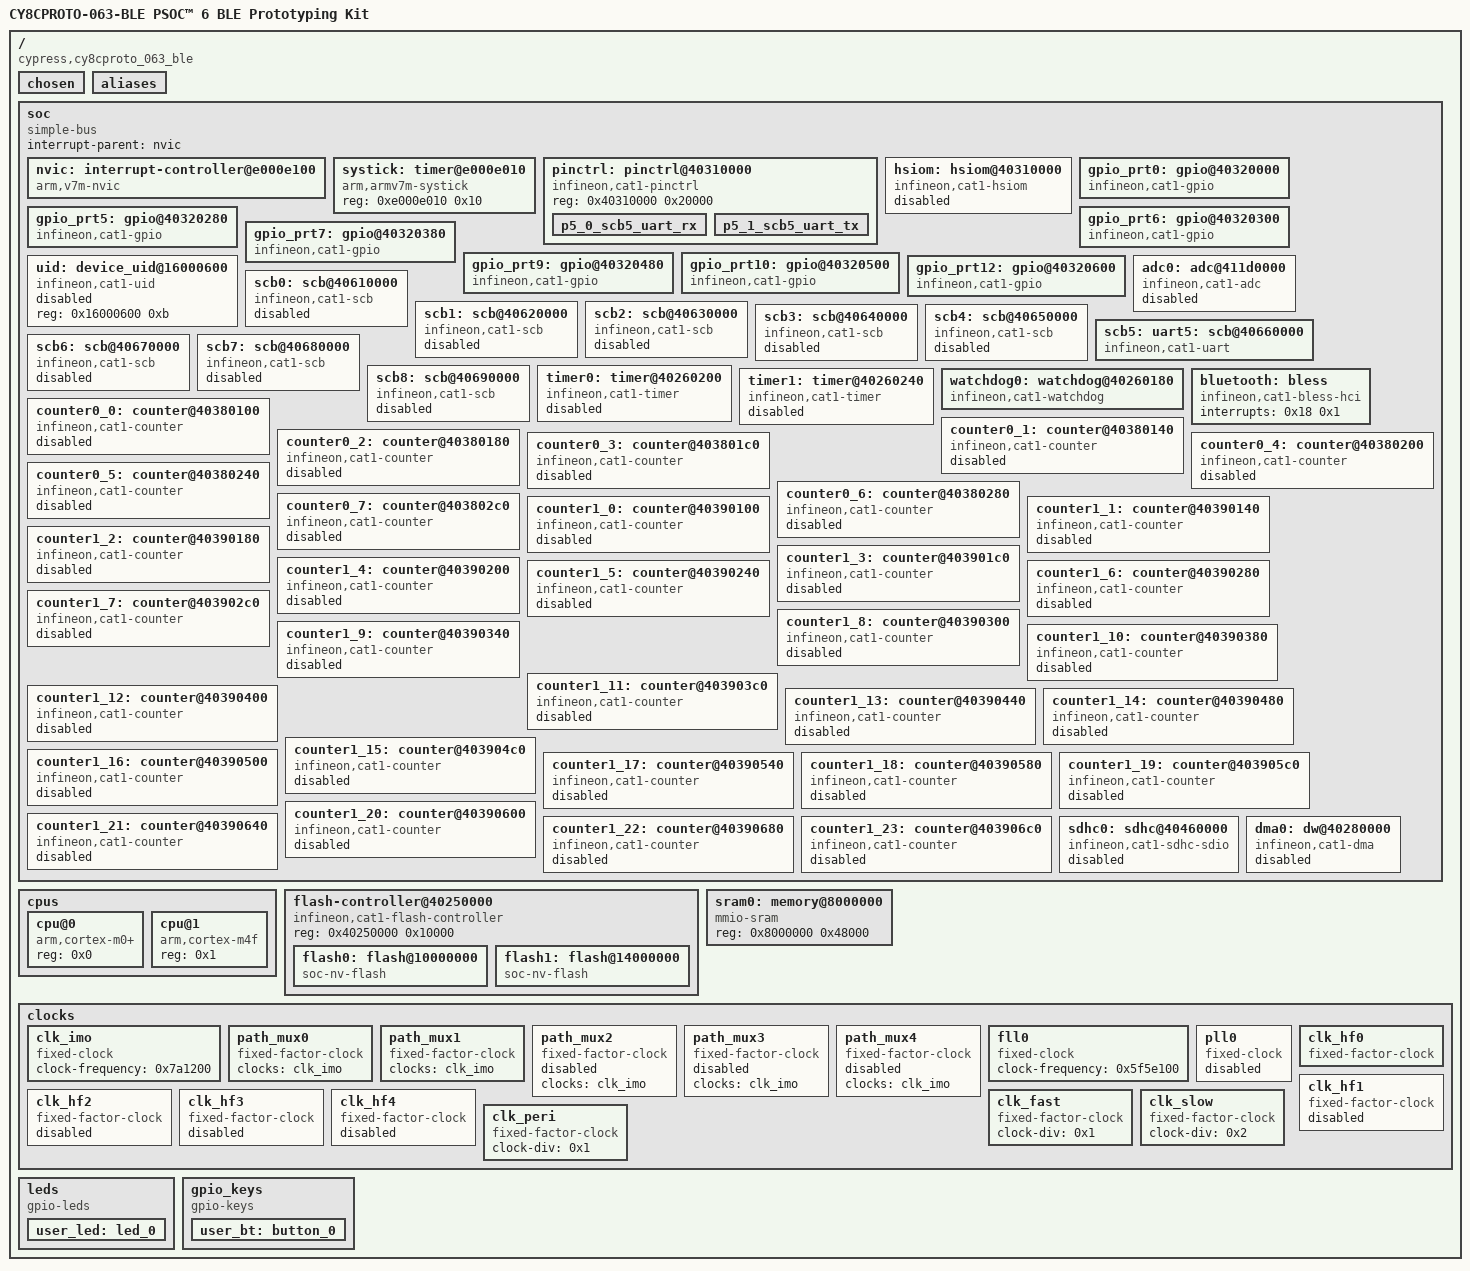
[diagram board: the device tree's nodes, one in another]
/dts-v1/;

/* node '/' defined in zephyr/dts/common/skeleton.dtsi:9 */
/ {
	#address-cells = < 0x1 >;                                /* in zephyr/dts/common/skeleton.dtsi:10 */
	#size-cells = < 0x1 >;                                   /* in zephyr/dts/common/skeleton.dtsi:11 */
	model = "CY8CPROTO-063-BLE PSOC™ 6 BLE Prototyping Kit"; /* in zephyr/boards/infineon/cy8cproto_063_ble/cy8cproto_063_ble.dts:15 */
	compatible = "cypress,cy8cproto_063_ble",
	             "cypress,PSOC6";                            /* in zephyr/boards/infineon/cy8cproto_063_ble/cy8cproto_063_ble.dts:16 */

	/* node '/chosen' defined in zephyr/dts/common/skeleton.dtsi:13 */
	chosen {
		zephyr,sram = &sram0;       /* in zephyr/boards/infineon/cy8cproto_063_ble/cy8cproto_063_ble.dts:26 */
		zephyr,flash = &flash0;     /* in zephyr/boards/infineon/cy8cproto_063_ble/cy8cproto_063_ble.dts:27 */
		zephyr,console = &uart5;    /* in zephyr/boards/infineon/cy8cproto_063_ble/cy8cproto_063_ble.dts:28 */
		zephyr,shell-uart = &uart5; /* in zephyr/boards/infineon/cy8cproto_063_ble/cy8cproto_063_ble.dts:29 */
		zephyr,bt-hci = &bluetooth; /* in zephyr/boards/infineon/cy8cproto_063_ble/cy8cproto_063_ble.dts:30 */
	};

	/* node '/aliases' defined in zephyr/dts/common/skeleton.dtsi:15 */
	aliases {
		uart-5 = &uart5;        /* in zephyr/boards/infineon/cy8cproto_063_ble/cy8cproto_063_ble.dts:19 */
		led0 = &user_led;       /* in zephyr/boards/infineon/cy8cproto_063_ble/cy8cproto_063_ble.dts:20 */
		sw0 = &user_bt;         /* in zephyr/boards/infineon/cy8cproto_063_ble/cy8cproto_063_ble.dts:21 */
		watchdog0 = &watchdog0; /* in zephyr/boards/infineon/cy8cproto_063_ble/cy8cproto_063_ble.dts:22 */
	};

	/* node '/soc' defined in zephyr/dts/arm/armv7-m.dtsi:6 */
	soc {
		#address-cells = < 0x1 >;     /* in zephyr/dts/arm/armv7-m.dtsi:7 */
		#size-cells = < 0x1 >;        /* in zephyr/dts/arm/armv7-m.dtsi:8 */
		compatible = "simple-bus";    /* in zephyr/dts/arm/armv7-m.dtsi:9 */
		interrupt-parent = < &nvic >; /* in zephyr/dts/arm/armv7-m.dtsi:10 */
		ranges;                       /* in zephyr/dts/arm/armv7-m.dtsi:11 */

		/* node '/soc/interrupt-controller@e000e100' defined in zephyr/dts/arm/armv7-m.dtsi:13 */
		nvic: interrupt-controller@e000e100 {
			#address-cells = < 0x1 >;            /* in zephyr/dts/arm/armv7-m.dtsi:14 */
			compatible = "arm,v7m-nvic";         /* in zephyr/dts/arm/armv7-m.dtsi:15 */
			reg = < 0xe000e100 0xc00 >;          /* in zephyr/dts/arm/armv7-m.dtsi:16 */
			interrupt-controller;                /* in zephyr/dts/arm/armv7-m.dtsi:17 */
			#interrupt-cells = < 0x2 >;          /* in zephyr/dts/arm/armv7-m.dtsi:18 */
			arm,num-irq-priority-bits = < 0x3 >; /* in zephyr/dts/arm/infineon/cat1a/mpns/CYBLE_416045_02.dtsi:12 */
			phandle = < 0x1 >;                   /* in zephyr/dts/arm/armv7-m.dtsi:10 */
		};

		/* node '/soc/timer@e000e010' defined in zephyr/dts/arm/armv7-m.dtsi:21 */
		systick: timer@e000e010 {
			compatible = "arm,armv7m-systick"; /* in zephyr/dts/arm/armv7-m.dtsi:22 */
			reg = < 0xe000e010 0x10 >;         /* in zephyr/dts/arm/armv7-m.dtsi:23 */
		};

		/* node '/soc/pinctrl@40310000' defined in zephyr/dts/arm/infineon/cat1a/psoc6_01/psoc6_01.dtsi:55 */
		pinctrl: pinctrl@40310000 {
			compatible = "infineon,cat1-pinctrl"; /* in zephyr/dts/arm/infineon/cat1a/psoc6_01/psoc6_01.dtsi:56 */
			reg = < 0x40310000 0x20000 >;         /* in zephyr/dts/arm/infineon/cat1a/psoc6_01/psoc6_01.dtsi:57 */
			#address-cells = < 0x1 >;             /* in zephyr/dts/arm/infineon/cat1a/psoc6_01/psoc6_01.dtsi:58 */
			#size-cells = < 0x0 >;                /* in zephyr/dts/arm/infineon/cat1a/psoc6_01/psoc6_01.dtsi:59 */

			/* node '/soc/pinctrl@40310000/p5_0_scb5_uart_rx' defined in zephyr/dts/arm/infineon/cat1a/psoc6_01/psoc6_01.43-smt.dtsi:125 */
			p5_0_scb5_uart_rx: p5_0_scb5_uart_rx {
				pinmux = < 0x120005 >; /* in zephyr/dts/arm/infineon/cat1a/psoc6_01/psoc6_01.43-smt.dtsi:126 */
				input-enable;          /* in zephyr/boards/infineon/cy8cproto_063_ble/cy8cproto_063_ble-pinctrl.dtsi:13 */
				phandle = < 0x3 >;     /* in zephyr/boards/infineon/cy8cproto_063_ble/cy8cproto_063_ble.dts:89 */
			};

			/* node '/soc/pinctrl@40310000/p5_1_scb5_uart_tx' defined in zephyr/dts/arm/infineon/cat1a/psoc6_01/psoc6_01.43-smt.dtsi:142 */
			p5_1_scb5_uart_tx: p5_1_scb5_uart_tx {
				pinmux = < 0x120105 >; /* in zephyr/dts/arm/infineon/cat1a/psoc6_01/psoc6_01.43-smt.dtsi:143 */
				drive-push-pull;       /* in zephyr/boards/infineon/cy8cproto_063_ble/cy8cproto_063_ble-pinctrl.dtsi:9 */
				phandle = < 0x2 >;     /* in zephyr/boards/infineon/cy8cproto_063_ble/cy8cproto_063_ble.dts:89 */
			};
		};

		/* node '/soc/hsiom@40310000' defined in zephyr/dts/arm/infineon/cat1a/psoc6_01/psoc6_01.dtsi:62 */
		hsiom: hsiom@40310000 {
			compatible = "infineon,cat1-hsiom"; /* in zephyr/dts/arm/infineon/cat1a/psoc6_01/psoc6_01.dtsi:63 */
			reg = < 0x40310000 0x4000 >;        /* in zephyr/dts/arm/infineon/cat1a/psoc6_01/psoc6_01.dtsi:64 */
			interrupts = < 0xf 0x6 >,
			             < 0x10 0x6 >;          /* in zephyr/dts/arm/infineon/cat1a/psoc6_01/psoc6_01.dtsi:65 */
			status = "disabled";                /* in zephyr/dts/arm/infineon/cat1a/psoc6_01/psoc6_01.dtsi:66 */
		};

		/* node '/soc/gpio@40320000' defined in zephyr/dts/arm/infineon/cat1a/psoc6_01/psoc6_01.dtsi:69 */
		gpio_prt0: gpio@40320000 {
			compatible = "infineon,cat1-gpio"; /* in zephyr/dts/arm/infineon/cat1a/psoc6_01/psoc6_01.dtsi:70 */
			reg = < 0x40320000 0x80 >;         /* in zephyr/dts/arm/infineon/cat1a/psoc6_01/psoc6_01.dtsi:71 */
			interrupts = < 0x0 0x6 >;          /* in zephyr/dts/arm/infineon/cat1a/psoc6_01/psoc6_01.dtsi:72 */
			gpio-controller;                   /* in zephyr/dts/arm/infineon/cat1a/psoc6_01/psoc6_01.dtsi:73 */
			ngpios = < 0x6 >;                  /* in zephyr/dts/arm/infineon/cat1a/psoc6_01/psoc6_01.dtsi:74 */
			#gpio-cells = < 0x2 >;             /* in zephyr/dts/arm/infineon/cat1a/psoc6_01/psoc6_01.dtsi:76 */
			status = "okay";                   /* in zephyr/boards/infineon/cy8cproto_063_ble/cy8cproto_063_ble.dts:56 */
			phandle = < 0xb >;                 /* in zephyr/boards/infineon/cy8cproto_063_ble/cy8cproto_063_ble.dts:49 */
		};

		/* node '/soc/gpio@40320280' defined in zephyr/dts/arm/infineon/cat1a/psoc6_01/psoc6_01.dtsi:119 */
		gpio_prt5: gpio@40320280 {
			compatible = "infineon,cat1-gpio"; /* in zephyr/dts/arm/infineon/cat1a/psoc6_01/psoc6_01.dtsi:120 */
			reg = < 0x40320280 0x80 >;         /* in zephyr/dts/arm/infineon/cat1a/psoc6_01/psoc6_01.dtsi:121 */
			interrupts = < 0x5 0x6 >;          /* in zephyr/dts/arm/infineon/cat1a/psoc6_01/psoc6_01.dtsi:122 */
			gpio-controller;                   /* in zephyr/dts/arm/infineon/cat1a/psoc6_01/psoc6_01.dtsi:123 */
			ngpios = < 0x8 >;                  /* in zephyr/dts/arm/infineon/cat1a/psoc6_01/psoc6_01.dtsi:124 */
			#gpio-cells = < 0x2 >;             /* in zephyr/dts/arm/infineon/cat1a/psoc6_01/psoc6_01.dtsi:126 */
			status = "okay";                   /* in zephyr/boards/infineon/cy8cproto_063_ble/cy8cproto_063_ble.dts:60 */
		};

		/* node '/soc/gpio@40320300' defined in zephyr/dts/arm/infineon/cat1a/psoc6_01/psoc6_01.dtsi:129 */
		gpio_prt6: gpio@40320300 {
			compatible = "infineon,cat1-gpio"; /* in zephyr/dts/arm/infineon/cat1a/psoc6_01/psoc6_01.dtsi:130 */
			reg = < 0x40320300 0x80 >;         /* in zephyr/dts/arm/infineon/cat1a/psoc6_01/psoc6_01.dtsi:131 */
			interrupts = < 0x6 0x6 >;          /* in zephyr/dts/arm/infineon/cat1a/psoc6_01/psoc6_01.dtsi:132 */
			gpio-controller;                   /* in zephyr/dts/arm/infineon/cat1a/psoc6_01/psoc6_01.dtsi:133 */
			ngpios = < 0x8 >;                  /* in zephyr/dts/arm/infineon/cat1a/psoc6_01/psoc6_01.dtsi:134 */
			#gpio-cells = < 0x2 >;             /* in zephyr/dts/arm/infineon/cat1a/psoc6_01/psoc6_01.dtsi:136 */
			status = "okay";                   /* in zephyr/boards/infineon/cy8cproto_063_ble/cy8cproto_063_ble.dts:64 */
			phandle = < 0xa >;                 /* in zephyr/boards/infineon/cy8cproto_063_ble/cy8cproto_063_ble.dts:40 */
		};

		/* node '/soc/gpio@40320380' defined in zephyr/dts/arm/infineon/cat1a/psoc6_01/psoc6_01.dtsi:139 */
		gpio_prt7: gpio@40320380 {
			compatible = "infineon,cat1-gpio"; /* in zephyr/dts/arm/infineon/cat1a/psoc6_01/psoc6_01.dtsi:140 */
			reg = < 0x40320380 0x80 >;         /* in zephyr/dts/arm/infineon/cat1a/psoc6_01/psoc6_01.dtsi:141 */
			interrupts = < 0x7 0x6 >;          /* in zephyr/dts/arm/infineon/cat1a/psoc6_01/psoc6_01.dtsi:142 */
			gpio-controller;                   /* in zephyr/dts/arm/infineon/cat1a/psoc6_01/psoc6_01.dtsi:143 */
			ngpios = < 0x8 >;                  /* in zephyr/dts/arm/infineon/cat1a/psoc6_01/psoc6_01.dtsi:144 */
			#gpio-cells = < 0x2 >;             /* in zephyr/dts/arm/infineon/cat1a/psoc6_01/psoc6_01.dtsi:146 */
			status = "okay";                   /* in zephyr/boards/infineon/cy8cproto_063_ble/cy8cproto_063_ble.dts:68 */
		};

		/* node '/soc/gpio@40320480' defined in zephyr/dts/arm/infineon/cat1a/psoc6_01/psoc6_01.dtsi:159 */
		gpio_prt9: gpio@40320480 {
			compatible = "infineon,cat1-gpio"; /* in zephyr/dts/arm/infineon/cat1a/psoc6_01/psoc6_01.dtsi:160 */
			reg = < 0x40320480 0x80 >;         /* in zephyr/dts/arm/infineon/cat1a/psoc6_01/psoc6_01.dtsi:161 */
			interrupts = < 0x9 0x6 >;          /* in zephyr/dts/arm/infineon/cat1a/psoc6_01/psoc6_01.dtsi:162 */
			gpio-controller;                   /* in zephyr/dts/arm/infineon/cat1a/psoc6_01/psoc6_01.dtsi:163 */
			ngpios = < 0x8 >;                  /* in zephyr/dts/arm/infineon/cat1a/psoc6_01/psoc6_01.dtsi:164 */
			#gpio-cells = < 0x2 >;             /* in zephyr/dts/arm/infineon/cat1a/psoc6_01/psoc6_01.dtsi:166 */
			status = "okay";                   /* in zephyr/boards/infineon/cy8cproto_063_ble/cy8cproto_063_ble.dts:72 */
		};

		/* node '/soc/gpio@40320500' defined in zephyr/dts/arm/infineon/cat1a/psoc6_01/psoc6_01.dtsi:169 */
		gpio_prt10: gpio@40320500 {
			compatible = "infineon,cat1-gpio"; /* in zephyr/dts/arm/infineon/cat1a/psoc6_01/psoc6_01.dtsi:170 */
			reg = < 0x40320500 0x80 >;         /* in zephyr/dts/arm/infineon/cat1a/psoc6_01/psoc6_01.dtsi:171 */
			interrupts = < 0xa 0x6 >;          /* in zephyr/dts/arm/infineon/cat1a/psoc6_01/psoc6_01.dtsi:172 */
			gpio-controller;                   /* in zephyr/dts/arm/infineon/cat1a/psoc6_01/psoc6_01.dtsi:173 */
			ngpios = < 0x8 >;                  /* in zephyr/dts/arm/infineon/cat1a/psoc6_01/psoc6_01.dtsi:174 */
			#gpio-cells = < 0x2 >;             /* in zephyr/dts/arm/infineon/cat1a/psoc6_01/psoc6_01.dtsi:176 */
			status = "okay";                   /* in zephyr/boards/infineon/cy8cproto_063_ble/cy8cproto_063_ble.dts:76 */
		};

		/* node '/soc/gpio@40320600' defined in zephyr/dts/arm/infineon/cat1a/psoc6_01/psoc6_01.dtsi:189 */
		gpio_prt12: gpio@40320600 {
			compatible = "infineon,cat1-gpio"; /* in zephyr/dts/arm/infineon/cat1a/psoc6_01/psoc6_01.dtsi:190 */
			reg = < 0x40320600 0x80 >;         /* in zephyr/dts/arm/infineon/cat1a/psoc6_01/psoc6_01.dtsi:191 */
			interrupts = < 0xc 0x6 >;          /* in zephyr/dts/arm/infineon/cat1a/psoc6_01/psoc6_01.dtsi:192 */
			gpio-controller;                   /* in zephyr/dts/arm/infineon/cat1a/psoc6_01/psoc6_01.dtsi:193 */
			ngpios = < 0x8 >;                  /* in zephyr/dts/arm/infineon/cat1a/psoc6_01/psoc6_01.dtsi:194 */
			#gpio-cells = < 0x2 >;             /* in zephyr/dts/arm/infineon/cat1a/psoc6_01/psoc6_01.dtsi:196 */
			status = "okay";                   /* in zephyr/boards/infineon/cy8cproto_063_ble/cy8cproto_063_ble.dts:80 */
		};

		/* node '/soc/device_uid@16000600' defined in zephyr/dts/arm/infineon/cat1a/psoc6_01/psoc6_01.dtsi:219 */
		uid: device_uid@16000600 {
			compatible = "infineon,cat1-uid"; /* in zephyr/dts/arm/infineon/cat1a/psoc6_01/psoc6_01.dtsi:220 */
			reg = < 0x16000600 0xb >;         /* in zephyr/dts/arm/infineon/cat1a/psoc6_01/psoc6_01.dtsi:221 */
			status = "disabled";              /* in zephyr/dts/arm/infineon/cat1a/psoc6_01/psoc6_01.dtsi:222 */
		};

		/* node '/soc/adc@411d0000' defined in zephyr/dts/arm/infineon/cat1a/psoc6_01/psoc6_01.dtsi:225 */
		adc0: adc@411d0000 {
			compatible = "infineon,cat1-adc"; /* in zephyr/dts/arm/infineon/cat1a/psoc6_01/psoc6_01.dtsi:226 */
			reg = < 0x411d0000 0x10000 >;     /* in zephyr/dts/arm/infineon/cat1a/psoc6_01/psoc6_01.dtsi:227 */
			interrupts = < 0x8a 0x6 >;        /* in zephyr/dts/arm/infineon/cat1a/psoc6_01/psoc6_01.dtsi:228 */
			status = "disabled";              /* in zephyr/dts/arm/infineon/cat1a/psoc6_01/psoc6_01.dtsi:229 */
			#io-channel-cells = < 0x1 >;      /* in zephyr/dts/arm/infineon/cat1a/psoc6_01/psoc6_01.dtsi:230 */
		};

		/* node '/soc/scb@40610000' defined in zephyr/dts/arm/infineon/cat1a/psoc6_01/psoc6_01.dtsi:233 */
		scb0: scb@40610000 {
			compatible = "infineon,cat1-scb"; /* in zephyr/dts/arm/infineon/cat1a/psoc6_01/psoc6_01.dtsi:234 */
			reg = < 0x40610000 0x10000 >;     /* in zephyr/dts/arm/infineon/cat1a/psoc6_01/psoc6_01.dtsi:235 */
			#address-cells = < 0x1 >;         /* in zephyr/dts/arm/infineon/cat1a/psoc6_01/psoc6_01.dtsi:236 */
			#size-cells = < 0x0 >;            /* in zephyr/dts/arm/infineon/cat1a/psoc6_01/psoc6_01.dtsi:237 */
			interrupts = < 0x29 0x6 >;        /* in zephyr/dts/arm/infineon/cat1a/psoc6_01/psoc6_01.dtsi:238 */
			status = "disabled";              /* in zephyr/dts/arm/infineon/cat1a/psoc6_01/psoc6_01.dtsi:239 */
		};

		/* node '/soc/scb@40620000' defined in zephyr/dts/arm/infineon/cat1a/psoc6_01/psoc6_01.dtsi:242 */
		scb1: scb@40620000 {
			compatible = "infineon,cat1-scb"; /* in zephyr/dts/arm/infineon/cat1a/psoc6_01/psoc6_01.dtsi:243 */
			reg = < 0x40620000 0x10000 >;     /* in zephyr/dts/arm/infineon/cat1a/psoc6_01/psoc6_01.dtsi:244 */
			#address-cells = < 0x1 >;         /* in zephyr/dts/arm/infineon/cat1a/psoc6_01/psoc6_01.dtsi:245 */
			#size-cells = < 0x0 >;            /* in zephyr/dts/arm/infineon/cat1a/psoc6_01/psoc6_01.dtsi:246 */
			interrupts = < 0x2a 0x6 >;        /* in zephyr/dts/arm/infineon/cat1a/psoc6_01/psoc6_01.dtsi:247 */
			status = "disabled";              /* in zephyr/dts/arm/infineon/cat1a/psoc6_01/psoc6_01.dtsi:248 */
		};

		/* node '/soc/scb@40630000' defined in zephyr/dts/arm/infineon/cat1a/psoc6_01/psoc6_01.dtsi:251 */
		scb2: scb@40630000 {
			compatible = "infineon,cat1-scb"; /* in zephyr/dts/arm/infineon/cat1a/psoc6_01/psoc6_01.dtsi:252 */
			reg = < 0x40630000 0x10000 >;     /* in zephyr/dts/arm/infineon/cat1a/psoc6_01/psoc6_01.dtsi:253 */
			#address-cells = < 0x1 >;         /* in zephyr/dts/arm/infineon/cat1a/psoc6_01/psoc6_01.dtsi:254 */
			#size-cells = < 0x0 >;            /* in zephyr/dts/arm/infineon/cat1a/psoc6_01/psoc6_01.dtsi:255 */
			interrupts = < 0x2b 0x6 >;        /* in zephyr/dts/arm/infineon/cat1a/psoc6_01/psoc6_01.dtsi:256 */
			status = "disabled";              /* in zephyr/dts/arm/infineon/cat1a/psoc6_01/psoc6_01.dtsi:257 */
		};

		/* node '/soc/scb@40640000' defined in zephyr/dts/arm/infineon/cat1a/psoc6_01/psoc6_01.dtsi:260 */
		scb3: scb@40640000 {
			compatible = "infineon,cat1-scb"; /* in zephyr/dts/arm/infineon/cat1a/psoc6_01/psoc6_01.dtsi:261 */
			reg = < 0x40640000 0x10000 >;     /* in zephyr/dts/arm/infineon/cat1a/psoc6_01/psoc6_01.dtsi:262 */
			#address-cells = < 0x1 >;         /* in zephyr/dts/arm/infineon/cat1a/psoc6_01/psoc6_01.dtsi:263 */
			#size-cells = < 0x0 >;            /* in zephyr/dts/arm/infineon/cat1a/psoc6_01/psoc6_01.dtsi:264 */
			interrupts = < 0x2c 0x6 >;        /* in zephyr/dts/arm/infineon/cat1a/psoc6_01/psoc6_01.dtsi:265 */
			status = "disabled";              /* in zephyr/dts/arm/infineon/cat1a/psoc6_01/psoc6_01.dtsi:266 */
		};

		/* node '/soc/scb@40650000' defined in zephyr/dts/arm/infineon/cat1a/psoc6_01/psoc6_01.dtsi:269 */
		scb4: scb@40650000 {
			compatible = "infineon,cat1-scb"; /* in zephyr/dts/arm/infineon/cat1a/psoc6_01/psoc6_01.dtsi:270 */
			reg = < 0x40650000 0x10000 >;     /* in zephyr/dts/arm/infineon/cat1a/psoc6_01/psoc6_01.dtsi:271 */
			#address-cells = < 0x1 >;         /* in zephyr/dts/arm/infineon/cat1a/psoc6_01/psoc6_01.dtsi:272 */
			#size-cells = < 0x0 >;            /* in zephyr/dts/arm/infineon/cat1a/psoc6_01/psoc6_01.dtsi:273 */
			interrupts = < 0x2d 0x6 >;        /* in zephyr/dts/arm/infineon/cat1a/psoc6_01/psoc6_01.dtsi:274 */
			status = "disabled";              /* in zephyr/dts/arm/infineon/cat1a/psoc6_01/psoc6_01.dtsi:275 */
		};

		/* node '/soc/scb@40660000' defined in zephyr/dts/arm/infineon/cat1a/psoc6_01/psoc6_01.dtsi:278 */
		scb5: uart5: scb@40660000 {
			reg = < 0x40660000 0x10000 >;                          /* in zephyr/dts/arm/infineon/cat1a/psoc6_01/psoc6_01.dtsi:280 */
			#address-cells = < 0x1 >;                              /* in zephyr/dts/arm/infineon/cat1a/psoc6_01/psoc6_01.dtsi:281 */
			#size-cells = < 0x0 >;                                 /* in zephyr/dts/arm/infineon/cat1a/psoc6_01/psoc6_01.dtsi:282 */
			interrupts = < 0x2e 0x6 >;                             /* in zephyr/dts/arm/infineon/cat1a/psoc6_01/psoc6_01.dtsi:283 */
			compatible = "infineon,cat1-uart";                     /* in zephyr/boards/infineon/cy8cproto_063_ble/cy8cproto_063_ble.dts:84 */
			status = "okay";                                       /* in zephyr/boards/infineon/cy8cproto_063_ble/cy8cproto_063_ble.dts:85 */
			current-speed = < 0x1c200 >;                           /* in zephyr/boards/infineon/cy8cproto_063_ble/cy8cproto_063_ble.dts:86 */
			pinctrl-0 = < &p5_1_scb5_uart_tx &p5_0_scb5_uart_rx >; /* in zephyr/boards/infineon/cy8cproto_063_ble/cy8cproto_063_ble.dts:89 */
			pinctrl-names = "default";                             /* in zephyr/boards/infineon/cy8cproto_063_ble/cy8cproto_063_ble.dts:90 */
		};

		/* node '/soc/scb@40670000' defined in zephyr/dts/arm/infineon/cat1a/psoc6_01/psoc6_01.dtsi:287 */
		scb6: scb@40670000 {
			compatible = "infineon,cat1-scb"; /* in zephyr/dts/arm/infineon/cat1a/psoc6_01/psoc6_01.dtsi:288 */
			reg = < 0x40670000 0x10000 >;     /* in zephyr/dts/arm/infineon/cat1a/psoc6_01/psoc6_01.dtsi:289 */
			#address-cells = < 0x1 >;         /* in zephyr/dts/arm/infineon/cat1a/psoc6_01/psoc6_01.dtsi:290 */
			#size-cells = < 0x0 >;            /* in zephyr/dts/arm/infineon/cat1a/psoc6_01/psoc6_01.dtsi:291 */
			interrupts = < 0x2f 0x6 >;        /* in zephyr/dts/arm/infineon/cat1a/psoc6_01/psoc6_01.dtsi:292 */
			status = "disabled";              /* in zephyr/dts/arm/infineon/cat1a/psoc6_01/psoc6_01.dtsi:293 */
		};

		/* node '/soc/scb@40680000' defined in zephyr/dts/arm/infineon/cat1a/psoc6_01/psoc6_01.dtsi:296 */
		scb7: scb@40680000 {
			compatible = "infineon,cat1-scb"; /* in zephyr/dts/arm/infineon/cat1a/psoc6_01/psoc6_01.dtsi:297 */
			reg = < 0x40680000 0x10000 >;     /* in zephyr/dts/arm/infineon/cat1a/psoc6_01/psoc6_01.dtsi:298 */
			#address-cells = < 0x1 >;         /* in zephyr/dts/arm/infineon/cat1a/psoc6_01/psoc6_01.dtsi:299 */
			#size-cells = < 0x0 >;            /* in zephyr/dts/arm/infineon/cat1a/psoc6_01/psoc6_01.dtsi:300 */
			interrupts = < 0x30 0x6 >;        /* in zephyr/dts/arm/infineon/cat1a/psoc6_01/psoc6_01.dtsi:301 */
			status = "disabled";              /* in zephyr/dts/arm/infineon/cat1a/psoc6_01/psoc6_01.dtsi:302 */
		};

		/* node '/soc/scb@40690000' defined in zephyr/dts/arm/infineon/cat1a/psoc6_01/psoc6_01.dtsi:305 */
		scb8: scb@40690000 {
			compatible = "infineon,cat1-scb"; /* in zephyr/dts/arm/infineon/cat1a/psoc6_01/psoc6_01.dtsi:306 */
			reg = < 0x40690000 0x10000 >;     /* in zephyr/dts/arm/infineon/cat1a/psoc6_01/psoc6_01.dtsi:307 */
			#address-cells = < 0x1 >;         /* in zephyr/dts/arm/infineon/cat1a/psoc6_01/psoc6_01.dtsi:308 */
			#size-cells = < 0x0 >;            /* in zephyr/dts/arm/infineon/cat1a/psoc6_01/psoc6_01.dtsi:309 */
			interrupts = < 0x12 0x6 >;        /* in zephyr/dts/arm/infineon/cat1a/psoc6_01/psoc6_01.dtsi:310 */
			status = "disabled";              /* in zephyr/dts/arm/infineon/cat1a/psoc6_01/psoc6_01.dtsi:311 */
		};

		/* node '/soc/timer@40260200' defined in zephyr/dts/arm/infineon/cat1a/psoc6_01/psoc6_01.dtsi:314 */
		timer0: timer@40260200 {
			compatible = "infineon,cat1-timer"; /* in zephyr/dts/arm/infineon/cat1a/psoc6_01/psoc6_01.dtsi:315 */
			reg = < 0x40260200 0x40 >;          /* in zephyr/dts/arm/infineon/cat1a/psoc6_01/psoc6_01.dtsi:316 */
			interrupts = < 0x13 0x6 >;          /* in zephyr/dts/arm/infineon/cat1a/psoc6_01/psoc6_01.dtsi:317 */
			status = "disabled";                /* in zephyr/dts/arm/infineon/cat1a/psoc6_01/psoc6_01.dtsi:318 */
		};

		/* node '/soc/timer@40260240' defined in zephyr/dts/arm/infineon/cat1a/psoc6_01/psoc6_01.dtsi:321 */
		timer1: timer@40260240 {
			compatible = "infineon,cat1-timer"; /* in zephyr/dts/arm/infineon/cat1a/psoc6_01/psoc6_01.dtsi:322 */
			reg = < 0x40260240 0x40 >;          /* in zephyr/dts/arm/infineon/cat1a/psoc6_01/psoc6_01.dtsi:323 */
			interrupts = < 0x14 0x6 >;          /* in zephyr/dts/arm/infineon/cat1a/psoc6_01/psoc6_01.dtsi:324 */
			status = "disabled";                /* in zephyr/dts/arm/infineon/cat1a/psoc6_01/psoc6_01.dtsi:325 */
		};

		/* node '/soc/watchdog@40260180' defined in zephyr/dts/arm/infineon/cat1a/psoc6_01/psoc6_01.dtsi:328 */
		watchdog0: watchdog@40260180 {
			compatible = "infineon,cat1-watchdog"; /* in zephyr/dts/arm/infineon/cat1a/psoc6_01/psoc6_01.dtsi:329 */
			reg = < 0x40260180 0xc >;              /* in zephyr/dts/arm/infineon/cat1a/psoc6_01/psoc6_01.dtsi:330 */
			interrupts = < 0x16 0x6 >;             /* in zephyr/dts/arm/infineon/cat1a/psoc6_01/psoc6_01.dtsi:331 */
			status = "okay";                       /* in zephyr/boards/infineon/cy8cproto_063_ble/cy8cproto_063_ble.dts:130 */
		};

		/* node '/soc/bless' defined in zephyr/dts/arm/infineon/cat1a/psoc6_01/psoc6_01.dtsi:335 */
		bluetooth: bless {
			compatible = "infineon,cat1-bless-hci"; /* in zephyr/dts/arm/infineon/cat1a/psoc6_01/psoc6_01.dtsi:336 */
			interrupts = < 0x18 0x1 >;              /* in zephyr/dts/arm/infineon/cat1a/psoc6_01/psoc6_01.dtsi:337 */
			status = "okay";                        /* in zephyr/boards/infineon/cy8cproto_063_ble/cy8cproto_063_ble.dts:126 */
		};

		/* node '/soc/counter@40380100' defined in zephyr/dts/arm/infineon/cat1a/psoc6_01/psoc6_01.dtsi:341 */
		counter0_0: counter@40380100 {
			compatible = "infineon,cat1-counter"; /* in zephyr/dts/arm/infineon/cat1a/psoc6_01/psoc6_01.dtsi:342 */
			reg = < 0x40380100 0x40 >;            /* in zephyr/dts/arm/infineon/cat1a/psoc6_01/psoc6_01.dtsi:343 */
			interrupts = < 0x5a 0x6 >;            /* in zephyr/dts/arm/infineon/cat1a/psoc6_01/psoc6_01.dtsi:344 */
			resolution = < 0x20 >;                /* in zephyr/dts/arm/infineon/cat1a/psoc6_01/psoc6_01.dtsi:345 */
			status = "disabled";                  /* in zephyr/dts/arm/infineon/cat1a/psoc6_01/psoc6_01.dtsi:346 */
		};

		/* node '/soc/counter@40380140' defined in zephyr/dts/arm/infineon/cat1a/psoc6_01/psoc6_01.dtsi:349 */
		counter0_1: counter@40380140 {
			compatible = "infineon,cat1-counter"; /* in zephyr/dts/arm/infineon/cat1a/psoc6_01/psoc6_01.dtsi:350 */
			reg = < 0x40380140 0x40 >;            /* in zephyr/dts/arm/infineon/cat1a/psoc6_01/psoc6_01.dtsi:351 */
			interrupts = < 0x5b 0x6 >;            /* in zephyr/dts/arm/infineon/cat1a/psoc6_01/psoc6_01.dtsi:352 */
			resolution = < 0x20 >;                /* in zephyr/dts/arm/infineon/cat1a/psoc6_01/psoc6_01.dtsi:353 */
			status = "disabled";                  /* in zephyr/dts/arm/infineon/cat1a/psoc6_01/psoc6_01.dtsi:354 */
		};

		/* node '/soc/counter@40380180' defined in zephyr/dts/arm/infineon/cat1a/psoc6_01/psoc6_01.dtsi:357 */
		counter0_2: counter@40380180 {
			compatible = "infineon,cat1-counter"; /* in zephyr/dts/arm/infineon/cat1a/psoc6_01/psoc6_01.dtsi:358 */
			reg = < 0x40380180 0x40 >;            /* in zephyr/dts/arm/infineon/cat1a/psoc6_01/psoc6_01.dtsi:359 */
			interrupts = < 0x5c 0x6 >;            /* in zephyr/dts/arm/infineon/cat1a/psoc6_01/psoc6_01.dtsi:360 */
			resolution = < 0x20 >;                /* in zephyr/dts/arm/infineon/cat1a/psoc6_01/psoc6_01.dtsi:361 */
			status = "disabled";                  /* in zephyr/dts/arm/infineon/cat1a/psoc6_01/psoc6_01.dtsi:362 */
		};

		/* node '/soc/counter@403801c0' defined in zephyr/dts/arm/infineon/cat1a/psoc6_01/psoc6_01.dtsi:365 */
		counter0_3: counter@403801c0 {
			compatible = "infineon,cat1-counter"; /* in zephyr/dts/arm/infineon/cat1a/psoc6_01/psoc6_01.dtsi:366 */
			reg = < 0x403801c0 0x40 >;            /* in zephyr/dts/arm/infineon/cat1a/psoc6_01/psoc6_01.dtsi:367 */
			interrupts = < 0x5d 0x6 >;            /* in zephyr/dts/arm/infineon/cat1a/psoc6_01/psoc6_01.dtsi:368 */
			resolution = < 0x20 >;                /* in zephyr/dts/arm/infineon/cat1a/psoc6_01/psoc6_01.dtsi:369 */
			status = "disabled";                  /* in zephyr/dts/arm/infineon/cat1a/psoc6_01/psoc6_01.dtsi:370 */
		};

		/* node '/soc/counter@40380200' defined in zephyr/dts/arm/infineon/cat1a/psoc6_01/psoc6_01.dtsi:373 */
		counter0_4: counter@40380200 {
			compatible = "infineon,cat1-counter"; /* in zephyr/dts/arm/infineon/cat1a/psoc6_01/psoc6_01.dtsi:374 */
			reg = < 0x40380200 0x40 >;            /* in zephyr/dts/arm/infineon/cat1a/psoc6_01/psoc6_01.dtsi:375 */
			interrupts = < 0x5e 0x6 >;            /* in zephyr/dts/arm/infineon/cat1a/psoc6_01/psoc6_01.dtsi:376 */
			resolution = < 0x20 >;                /* in zephyr/dts/arm/infineon/cat1a/psoc6_01/psoc6_01.dtsi:377 */
			status = "disabled";                  /* in zephyr/dts/arm/infineon/cat1a/psoc6_01/psoc6_01.dtsi:378 */
		};

		/* node '/soc/counter@40380240' defined in zephyr/dts/arm/infineon/cat1a/psoc6_01/psoc6_01.dtsi:381 */
		counter0_5: counter@40380240 {
			compatible = "infineon,cat1-counter"; /* in zephyr/dts/arm/infineon/cat1a/psoc6_01/psoc6_01.dtsi:382 */
			reg = < 0x40380240 0x40 >;            /* in zephyr/dts/arm/infineon/cat1a/psoc6_01/psoc6_01.dtsi:383 */
			interrupts = < 0x5f 0x6 >;            /* in zephyr/dts/arm/infineon/cat1a/psoc6_01/psoc6_01.dtsi:384 */
			resolution = < 0x20 >;                /* in zephyr/dts/arm/infineon/cat1a/psoc6_01/psoc6_01.dtsi:385 */
			status = "disabled";                  /* in zephyr/dts/arm/infineon/cat1a/psoc6_01/psoc6_01.dtsi:386 */
		};

		/* node '/soc/counter@40380280' defined in zephyr/dts/arm/infineon/cat1a/psoc6_01/psoc6_01.dtsi:389 */
		counter0_6: counter@40380280 {
			compatible = "infineon,cat1-counter"; /* in zephyr/dts/arm/infineon/cat1a/psoc6_01/psoc6_01.dtsi:390 */
			reg = < 0x40380280 0x40 >;            /* in zephyr/dts/arm/infineon/cat1a/psoc6_01/psoc6_01.dtsi:391 */
			interrupts = < 0x60 0x6 >;            /* in zephyr/dts/arm/infineon/cat1a/psoc6_01/psoc6_01.dtsi:392 */
			resolution = < 0x20 >;                /* in zephyr/dts/arm/infineon/cat1a/psoc6_01/psoc6_01.dtsi:393 */
			status = "disabled";                  /* in zephyr/dts/arm/infineon/cat1a/psoc6_01/psoc6_01.dtsi:394 */
		};

		/* node '/soc/counter@403802c0' defined in zephyr/dts/arm/infineon/cat1a/psoc6_01/psoc6_01.dtsi:397 */
		counter0_7: counter@403802c0 {
			compatible = "infineon,cat1-counter"; /* in zephyr/dts/arm/infineon/cat1a/psoc6_01/psoc6_01.dtsi:398 */
			reg = < 0x403802c0 0x40 >;            /* in zephyr/dts/arm/infineon/cat1a/psoc6_01/psoc6_01.dtsi:399 */
			interrupts = < 0x61 0x6 >;            /* in zephyr/dts/arm/infineon/cat1a/psoc6_01/psoc6_01.dtsi:400 */
			resolution = < 0x20 >;                /* in zephyr/dts/arm/infineon/cat1a/psoc6_01/psoc6_01.dtsi:401 */
			status = "disabled";                  /* in zephyr/dts/arm/infineon/cat1a/psoc6_01/psoc6_01.dtsi:402 */
		};

		/* node '/soc/counter@40390100' defined in zephyr/dts/arm/infineon/cat1a/psoc6_01/psoc6_01.dtsi:405 */
		counter1_0: counter@40390100 {
			compatible = "infineon,cat1-counter"; /* in zephyr/dts/arm/infineon/cat1a/psoc6_01/psoc6_01.dtsi:406 */
			reg = < 0x40390100 0x40 >;            /* in zephyr/dts/arm/infineon/cat1a/psoc6_01/psoc6_01.dtsi:407 */
			interrupts = < 0x62 0x6 >;            /* in zephyr/dts/arm/infineon/cat1a/psoc6_01/psoc6_01.dtsi:408 */
			resolution = < 0x10 >;                /* in zephyr/dts/arm/infineon/cat1a/psoc6_01/psoc6_01.dtsi:409 */
			status = "disabled";                  /* in zephyr/dts/arm/infineon/cat1a/psoc6_01/psoc6_01.dtsi:410 */
		};

		/* node '/soc/counter@40390140' defined in zephyr/dts/arm/infineon/cat1a/psoc6_01/psoc6_01.dtsi:413 */
		counter1_1: counter@40390140 {
			compatible = "infineon,cat1-counter"; /* in zephyr/dts/arm/infineon/cat1a/psoc6_01/psoc6_01.dtsi:414 */
			reg = < 0x40390140 0x40 >;            /* in zephyr/dts/arm/infineon/cat1a/psoc6_01/psoc6_01.dtsi:415 */
			interrupts = < 0x63 0x6 >;            /* in zephyr/dts/arm/infineon/cat1a/psoc6_01/psoc6_01.dtsi:416 */
			resolution = < 0x10 >;                /* in zephyr/dts/arm/infineon/cat1a/psoc6_01/psoc6_01.dtsi:417 */
			status = "disabled";                  /* in zephyr/dts/arm/infineon/cat1a/psoc6_01/psoc6_01.dtsi:418 */
		};

		/* node '/soc/counter@40390180' defined in zephyr/dts/arm/infineon/cat1a/psoc6_01/psoc6_01.dtsi:421 */
		counter1_2: counter@40390180 {
			compatible = "infineon,cat1-counter"; /* in zephyr/dts/arm/infineon/cat1a/psoc6_01/psoc6_01.dtsi:422 */
			reg = < 0x40390180 0x40 >;            /* in zephyr/dts/arm/infineon/cat1a/psoc6_01/psoc6_01.dtsi:423 */
			interrupts = < 0x64 0x6 >;            /* in zephyr/dts/arm/infineon/cat1a/psoc6_01/psoc6_01.dtsi:424 */
			resolution = < 0x10 >;                /* in zephyr/dts/arm/infineon/cat1a/psoc6_01/psoc6_01.dtsi:425 */
			status = "disabled";                  /* in zephyr/dts/arm/infineon/cat1a/psoc6_01/psoc6_01.dtsi:426 */
		};

		/* node '/soc/counter@403901c0' defined in zephyr/dts/arm/infineon/cat1a/psoc6_01/psoc6_01.dtsi:429 */
		counter1_3: counter@403901c0 {
			compatible = "infineon,cat1-counter"; /* in zephyr/dts/arm/infineon/cat1a/psoc6_01/psoc6_01.dtsi:430 */
			reg = < 0x403901c0 0x40 >;            /* in zephyr/dts/arm/infineon/cat1a/psoc6_01/psoc6_01.dtsi:431 */
			interrupts = < 0x65 0x6 >;            /* in zephyr/dts/arm/infineon/cat1a/psoc6_01/psoc6_01.dtsi:432 */
			resolution = < 0x10 >;                /* in zephyr/dts/arm/infineon/cat1a/psoc6_01/psoc6_01.dtsi:433 */
			status = "disabled";                  /* in zephyr/dts/arm/infineon/cat1a/psoc6_01/psoc6_01.dtsi:434 */
		};

		/* node '/soc/counter@40390200' defined in zephyr/dts/arm/infineon/cat1a/psoc6_01/psoc6_01.dtsi:437 */
		counter1_4: counter@40390200 {
			compatible = "infineon,cat1-counter"; /* in zephyr/dts/arm/infineon/cat1a/psoc6_01/psoc6_01.dtsi:438 */
			reg = < 0x40390200 0x40 >;            /* in zephyr/dts/arm/infineon/cat1a/psoc6_01/psoc6_01.dtsi:439 */
			interrupts = < 0x66 0x6 >;            /* in zephyr/dts/arm/infineon/cat1a/psoc6_01/psoc6_01.dtsi:440 */
			resolution = < 0x10 >;                /* in zephyr/dts/arm/infineon/cat1a/psoc6_01/psoc6_01.dtsi:441 */
			status = "disabled";                  /* in zephyr/dts/arm/infineon/cat1a/psoc6_01/psoc6_01.dtsi:442 */
		};

		/* node '/soc/counter@40390240' defined in zephyr/dts/arm/infineon/cat1a/psoc6_01/psoc6_01.dtsi:445 */
		counter1_5: counter@40390240 {
			compatible = "infineon,cat1-counter"; /* in zephyr/dts/arm/infineon/cat1a/psoc6_01/psoc6_01.dtsi:446 */
			reg = < 0x40390240 0x40 >;            /* in zephyr/dts/arm/infineon/cat1a/psoc6_01/psoc6_01.dtsi:447 */
			interrupts = < 0x67 0x6 >;            /* in zephyr/dts/arm/infineon/cat1a/psoc6_01/psoc6_01.dtsi:448 */
			resolution = < 0x10 >;                /* in zephyr/dts/arm/infineon/cat1a/psoc6_01/psoc6_01.dtsi:449 */
			status = "disabled";                  /* in zephyr/dts/arm/infineon/cat1a/psoc6_01/psoc6_01.dtsi:450 */
		};

		/* node '/soc/counter@40390280' defined in zephyr/dts/arm/infineon/cat1a/psoc6_01/psoc6_01.dtsi:453 */
		counter1_6: counter@40390280 {
			compatible = "infineon,cat1-counter"; /* in zephyr/dts/arm/infineon/cat1a/psoc6_01/psoc6_01.dtsi:454 */
			reg = < 0x40390280 0x40 >;            /* in zephyr/dts/arm/infineon/cat1a/psoc6_01/psoc6_01.dtsi:455 */
			interrupts = < 0x68 0x6 >;            /* in zephyr/dts/arm/infineon/cat1a/psoc6_01/psoc6_01.dtsi:456 */
			resolution = < 0x10 >;                /* in zephyr/dts/arm/infineon/cat1a/psoc6_01/psoc6_01.dtsi:457 */
			status = "disabled";                  /* in zephyr/dts/arm/infineon/cat1a/psoc6_01/psoc6_01.dtsi:458 */
		};

		/* node '/soc/counter@403902c0' defined in zephyr/dts/arm/infineon/cat1a/psoc6_01/psoc6_01.dtsi:461 */
		counter1_7: counter@403902c0 {
			compatible = "infineon,cat1-counter"; /* in zephyr/dts/arm/infineon/cat1a/psoc6_01/psoc6_01.dtsi:462 */
			reg = < 0x403902c0 0x40 >;            /* in zephyr/dts/arm/infineon/cat1a/psoc6_01/psoc6_01.dtsi:463 */
			interrupts = < 0x69 0x6 >;            /* in zephyr/dts/arm/infineon/cat1a/psoc6_01/psoc6_01.dtsi:464 */
			resolution = < 0x10 >;                /* in zephyr/dts/arm/infineon/cat1a/psoc6_01/psoc6_01.dtsi:465 */
			status = "disabled";                  /* in zephyr/dts/arm/infineon/cat1a/psoc6_01/psoc6_01.dtsi:466 */
		};

		/* node '/soc/counter@40390300' defined in zephyr/dts/arm/infineon/cat1a/psoc6_01/psoc6_01.dtsi:469 */
		counter1_8: counter@40390300 {
			compatible = "infineon,cat1-counter"; /* in zephyr/dts/arm/infineon/cat1a/psoc6_01/psoc6_01.dtsi:470 */
			reg = < 0x40390300 0x40 >;            /* in zephyr/dts/arm/infineon/cat1a/psoc6_01/psoc6_01.dtsi:471 */
			interrupts = < 0x6a 0x6 >;            /* in zephyr/dts/arm/infineon/cat1a/psoc6_01/psoc6_01.dtsi:472 */
			resolution = < 0x10 >;                /* in zephyr/dts/arm/infineon/cat1a/psoc6_01/psoc6_01.dtsi:473 */
			status = "disabled";                  /* in zephyr/dts/arm/infineon/cat1a/psoc6_01/psoc6_01.dtsi:474 */
		};

		/* node '/soc/counter@40390340' defined in zephyr/dts/arm/infineon/cat1a/psoc6_01/psoc6_01.dtsi:477 */
		counter1_9: counter@40390340 {
			compatible = "infineon,cat1-counter"; /* in zephyr/dts/arm/infineon/cat1a/psoc6_01/psoc6_01.dtsi:478 */
			reg = < 0x40390340 0x40 >;            /* in zephyr/dts/arm/infineon/cat1a/psoc6_01/psoc6_01.dtsi:479 */
			interrupts = < 0x6b 0x6 >;            /* in zephyr/dts/arm/infineon/cat1a/psoc6_01/psoc6_01.dtsi:480 */
			resolution = < 0x10 >;                /* in zephyr/dts/arm/infineon/cat1a/psoc6_01/psoc6_01.dtsi:481 */
			status = "disabled";                  /* in zephyr/dts/arm/infineon/cat1a/psoc6_01/psoc6_01.dtsi:482 */
		};

		/* node '/soc/counter@40390380' defined in zephyr/dts/arm/infineon/cat1a/psoc6_01/psoc6_01.dtsi:485 */
		counter1_10: counter@40390380 {
			compatible = "infineon,cat1-counter"; /* in zephyr/dts/arm/infineon/cat1a/psoc6_01/psoc6_01.dtsi:486 */
			reg = < 0x40390380 0x40 >;            /* in zephyr/dts/arm/infineon/cat1a/psoc6_01/psoc6_01.dtsi:487 */
			interrupts = < 0x6c 0x6 >;            /* in zephyr/dts/arm/infineon/cat1a/psoc6_01/psoc6_01.dtsi:488 */
			resolution = < 0x10 >;                /* in zephyr/dts/arm/infineon/cat1a/psoc6_01/psoc6_01.dtsi:489 */
			status = "disabled";                  /* in zephyr/dts/arm/infineon/cat1a/psoc6_01/psoc6_01.dtsi:490 */
		};

		/* node '/soc/counter@403903c0' defined in zephyr/dts/arm/infineon/cat1a/psoc6_01/psoc6_01.dtsi:493 */
		counter1_11: counter@403903c0 {
			compatible = "infineon,cat1-counter"; /* in zephyr/dts/arm/infineon/cat1a/psoc6_01/psoc6_01.dtsi:494 */
			reg = < 0x403903c0 0x40 >;            /* in zephyr/dts/arm/infineon/cat1a/psoc6_01/psoc6_01.dtsi:495 */
			interrupts = < 0x6d 0x6 >;            /* in zephyr/dts/arm/infineon/cat1a/psoc6_01/psoc6_01.dtsi:496 */
			resolution = < 0x10 >;                /* in zephyr/dts/arm/infineon/cat1a/psoc6_01/psoc6_01.dtsi:497 */
			status = "disabled";                  /* in zephyr/dts/arm/infineon/cat1a/psoc6_01/psoc6_01.dtsi:498 */
		};

		/* node '/soc/counter@40390400' defined in zephyr/dts/arm/infineon/cat1a/psoc6_01/psoc6_01.dtsi:501 */
		counter1_12: counter@40390400 {
			compatible = "infineon,cat1-counter"; /* in zephyr/dts/arm/infineon/cat1a/psoc6_01/psoc6_01.dtsi:502 */
			reg = < 0x40390400 0x40 >;            /* in zephyr/dts/arm/infineon/cat1a/psoc6_01/psoc6_01.dtsi:503 */
			interrupts = < 0x6e 0x6 >;            /* in zephyr/dts/arm/infineon/cat1a/psoc6_01/psoc6_01.dtsi:504 */
			resolution = < 0x10 >;                /* in zephyr/dts/arm/infineon/cat1a/psoc6_01/psoc6_01.dtsi:505 */
			status = "disabled";                  /* in zephyr/dts/arm/infineon/cat1a/psoc6_01/psoc6_01.dtsi:506 */
		};

		/* node '/soc/counter@40390440' defined in zephyr/dts/arm/infineon/cat1a/psoc6_01/psoc6_01.dtsi:509 */
		counter1_13: counter@40390440 {
			compatible = "infineon,cat1-counter"; /* in zephyr/dts/arm/infineon/cat1a/psoc6_01/psoc6_01.dtsi:510 */
			reg = < 0x40390440 0x40 >;            /* in zephyr/dts/arm/infineon/cat1a/psoc6_01/psoc6_01.dtsi:511 */
			interrupts = < 0x6f 0x6 >;            /* in zephyr/dts/arm/infineon/cat1a/psoc6_01/psoc6_01.dtsi:512 */
			resolution = < 0x10 >;                /* in zephyr/dts/arm/infineon/cat1a/psoc6_01/psoc6_01.dtsi:513 */
			status = "disabled";                  /* in zephyr/dts/arm/infineon/cat1a/psoc6_01/psoc6_01.dtsi:514 */
		};

		/* node '/soc/counter@40390480' defined in zephyr/dts/arm/infineon/cat1a/psoc6_01/psoc6_01.dtsi:517 */
		counter1_14: counter@40390480 {
			compatible = "infineon,cat1-counter"; /* in zephyr/dts/arm/infineon/cat1a/psoc6_01/psoc6_01.dtsi:518 */
			reg = < 0x40390480 0x40 >;            /* in zephyr/dts/arm/infineon/cat1a/psoc6_01/psoc6_01.dtsi:519 */
			interrupts = < 0x70 0x6 >;            /* in zephyr/dts/arm/infineon/cat1a/psoc6_01/psoc6_01.dtsi:520 */
			resolution = < 0x10 >;                /* in zephyr/dts/arm/infineon/cat1a/psoc6_01/psoc6_01.dtsi:521 */
			status = "disabled";                  /* in zephyr/dts/arm/infineon/cat1a/psoc6_01/psoc6_01.dtsi:522 */
		};

		/* node '/soc/counter@403904c0' defined in zephyr/dts/arm/infineon/cat1a/psoc6_01/psoc6_01.dtsi:525 */
		counter1_15: counter@403904c0 {
			compatible = "infineon,cat1-counter"; /* in zephyr/dts/arm/infineon/cat1a/psoc6_01/psoc6_01.dtsi:526 */
			reg = < 0x403904c0 0x40 >;            /* in zephyr/dts/arm/infineon/cat1a/psoc6_01/psoc6_01.dtsi:527 */
			interrupts = < 0x71 0x6 >;            /* in zephyr/dts/arm/infineon/cat1a/psoc6_01/psoc6_01.dtsi:528 */
			resolution = < 0x10 >;                /* in zephyr/dts/arm/infineon/cat1a/psoc6_01/psoc6_01.dtsi:529 */
			status = "disabled";                  /* in zephyr/dts/arm/infineon/cat1a/psoc6_01/psoc6_01.dtsi:530 */
		};

		/* node '/soc/counter@40390500' defined in zephyr/dts/arm/infineon/cat1a/psoc6_01/psoc6_01.dtsi:533 */
		counter1_16: counter@40390500 {
			compatible = "infineon,cat1-counter"; /* in zephyr/dts/arm/infineon/cat1a/psoc6_01/psoc6_01.dtsi:534 */
			reg = < 0x40390500 0x40 >;            /* in zephyr/dts/arm/infineon/cat1a/psoc6_01/psoc6_01.dtsi:535 */
			interrupts = < 0x72 0x6 >;            /* in zephyr/dts/arm/infineon/cat1a/psoc6_01/psoc6_01.dtsi:536 */
			resolution = < 0x10 >;                /* in zephyr/dts/arm/infineon/cat1a/psoc6_01/psoc6_01.dtsi:537 */
			status = "disabled";                  /* in zephyr/dts/arm/infineon/cat1a/psoc6_01/psoc6_01.dtsi:538 */
		};

		/* node '/soc/counter@40390540' defined in zephyr/dts/arm/infineon/cat1a/psoc6_01/psoc6_01.dtsi:541 */
		counter1_17: counter@40390540 {
			compatible = "infineon,cat1-counter"; /* in zephyr/dts/arm/infineon/cat1a/psoc6_01/psoc6_01.dtsi:542 */
			reg = < 0x40390540 0x40 >;            /* in zephyr/dts/arm/infineon/cat1a/psoc6_01/psoc6_01.dtsi:543 */
			interrupts = < 0x73 0x6 >;            /* in zephyr/dts/arm/infineon/cat1a/psoc6_01/psoc6_01.dtsi:544 */
			resolution = < 0x10 >;                /* in zephyr/dts/arm/infineon/cat1a/psoc6_01/psoc6_01.dtsi:545 */
			status = "disabled";                  /* in zephyr/dts/arm/infineon/cat1a/psoc6_01/psoc6_01.dtsi:546 */
		};

		/* node '/soc/counter@40390580' defined in zephyr/dts/arm/infineon/cat1a/psoc6_01/psoc6_01.dtsi:549 */
		counter1_18: counter@40390580 {
			compatible = "infineon,cat1-counter"; /* in zephyr/dts/arm/infineon/cat1a/psoc6_01/psoc6_01.dtsi:550 */
			reg = < 0x40390580 0x40 >;            /* in zephyr/dts/arm/infineon/cat1a/psoc6_01/psoc6_01.dtsi:551 */
			interrupts = < 0x74 0x6 >;            /* in zephyr/dts/arm/infineon/cat1a/psoc6_01/psoc6_01.dtsi:552 */
			resolution = < 0x10 >;                /* in zephyr/dts/arm/infineon/cat1a/psoc6_01/psoc6_01.dtsi:553 */
			status = "disabled";                  /* in zephyr/dts/arm/infineon/cat1a/psoc6_01/psoc6_01.dtsi:554 */
		};

		/* node '/soc/counter@403905c0' defined in zephyr/dts/arm/infineon/cat1a/psoc6_01/psoc6_01.dtsi:557 */
		counter1_19: counter@403905c0 {
			compatible = "infineon,cat1-counter"; /* in zephyr/dts/arm/infineon/cat1a/psoc6_01/psoc6_01.dtsi:558 */
			reg = < 0x403905c0 0x40 >;            /* in zephyr/dts/arm/infineon/cat1a/psoc6_01/psoc6_01.dtsi:559 */
			interrupts = < 0x75 0x6 >;            /* in zephyr/dts/arm/infineon/cat1a/psoc6_01/psoc6_01.dtsi:560 */
			resolution = < 0x10 >;                /* in zephyr/dts/arm/infineon/cat1a/psoc6_01/psoc6_01.dtsi:561 */
			status = "disabled";                  /* in zephyr/dts/arm/infineon/cat1a/psoc6_01/psoc6_01.dtsi:562 */
		};

		/* node '/soc/counter@40390600' defined in zephyr/dts/arm/infineon/cat1a/psoc6_01/psoc6_01.dtsi:565 */
		counter1_20: counter@40390600 {
			compatible = "infineon,cat1-counter"; /* in zephyr/dts/arm/infineon/cat1a/psoc6_01/psoc6_01.dtsi:566 */
			reg = < 0x40390600 0x40 >;            /* in zephyr/dts/arm/infineon/cat1a/psoc6_01/psoc6_01.dtsi:567 */
			interrupts = < 0x76 0x6 >;            /* in zephyr/dts/arm/infineon/cat1a/psoc6_01/psoc6_01.dtsi:568 */
			resolution = < 0x10 >;                /* in zephyr/dts/arm/infineon/cat1a/psoc6_01/psoc6_01.dtsi:569 */
			status = "disabled";                  /* in zephyr/dts/arm/infineon/cat1a/psoc6_01/psoc6_01.dtsi:570 */
		};

		/* node '/soc/counter@40390640' defined in zephyr/dts/arm/infineon/cat1a/psoc6_01/psoc6_01.dtsi:573 */
		counter1_21: counter@40390640 {
			compatible = "infineon,cat1-counter"; /* in zephyr/dts/arm/infineon/cat1a/psoc6_01/psoc6_01.dtsi:574 */
			reg = < 0x40390640 0x40 >;            /* in zephyr/dts/arm/infineon/cat1a/psoc6_01/psoc6_01.dtsi:575 */
			interrupts = < 0x77 0x6 >;            /* in zephyr/dts/arm/infineon/cat1a/psoc6_01/psoc6_01.dtsi:576 */
			resolution = < 0x10 >;                /* in zephyr/dts/arm/infineon/cat1a/psoc6_01/psoc6_01.dtsi:577 */
			status = "disabled";                  /* in zephyr/dts/arm/infineon/cat1a/psoc6_01/psoc6_01.dtsi:578 */
		};

		/* node '/soc/counter@40390680' defined in zephyr/dts/arm/infineon/cat1a/psoc6_01/psoc6_01.dtsi:581 */
		counter1_22: counter@40390680 {
			compatible = "infineon,cat1-counter"; /* in zephyr/dts/arm/infineon/cat1a/psoc6_01/psoc6_01.dtsi:582 */
			reg = < 0x40390680 0x40 >;            /* in zephyr/dts/arm/infineon/cat1a/psoc6_01/psoc6_01.dtsi:583 */
			interrupts = < 0x78 0x6 >;            /* in zephyr/dts/arm/infineon/cat1a/psoc6_01/psoc6_01.dtsi:584 */
			resolution = < 0x10 >;                /* in zephyr/dts/arm/infineon/cat1a/psoc6_01/psoc6_01.dtsi:585 */
			status = "disabled";                  /* in zephyr/dts/arm/infineon/cat1a/psoc6_01/psoc6_01.dtsi:586 */
		};

		/* node '/soc/counter@403906c0' defined in zephyr/dts/arm/infineon/cat1a/psoc6_01/psoc6_01.dtsi:589 */
		counter1_23: counter@403906c0 {
			compatible = "infineon,cat1-counter"; /* in zephyr/dts/arm/infineon/cat1a/psoc6_01/psoc6_01.dtsi:590 */
			reg = < 0x403906c0 0x40 >;            /* in zephyr/dts/arm/infineon/cat1a/psoc6_01/psoc6_01.dtsi:591 */
			interrupts = < 0x79 0x6 >;            /* in zephyr/dts/arm/infineon/cat1a/psoc6_01/psoc6_01.dtsi:592 */
			resolution = < 0x10 >;                /* in zephyr/dts/arm/infineon/cat1a/psoc6_01/psoc6_01.dtsi:593 */
			status = "disabled";                  /* in zephyr/dts/arm/infineon/cat1a/psoc6_01/psoc6_01.dtsi:594 */
		};

		/* node '/soc/sdhc@40460000' defined in zephyr/dts/arm/infineon/cat1a/psoc6_01/psoc6_01.dtsi:597 */
		sdhc0: sdhc@40460000 {
			compatible = "infineon,cat1-sdhc-sdio"; /* in zephyr/dts/arm/infineon/cat1a/psoc6_01/psoc6_01.dtsi:598 */
			reg = < 0x40460000 0x2000 >;            /* in zephyr/dts/arm/infineon/cat1a/psoc6_01/psoc6_01.dtsi:599 */
			interrupts = < 0xa4 0x6 >;              /* in zephyr/dts/arm/infineon/cat1a/psoc6_01/psoc6_01.dtsi:600 */
			status = "disabled";                    /* in zephyr/dts/arm/infineon/cat1a/psoc6_01/psoc6_01.dtsi:601 */
		};

		/* node '/soc/dw@40280000' defined in zephyr/dts/arm/infineon/cat1a/psoc6_01/psoc6_01.dtsi:604 */
		dma0: dw@40280000 {
			#dma-cells = < 0x1 >;             /* in zephyr/dts/arm/infineon/cat1a/psoc6_01/psoc6_01.dtsi:605 */
			compatible = "infineon,cat1-dma"; /* in zephyr/dts/arm/infineon/cat1a/psoc6_01/psoc6_01.dtsi:606 */
			reg = < 0x40280000 0x8700 >;      /* in zephyr/dts/arm/infineon/cat1a/psoc6_01/psoc6_01.dtsi:607 */
			dma-channels = < 0x10 >;          /* in zephyr/dts/arm/infineon/cat1a/psoc6_01/psoc6_01.dtsi:608 */
			interrupts = < 0x32 0x6 >,
			             < 0x33 0x6 >,
			             < 0x34 0x6 >,
			             < 0x35 0x6 >,
			             < 0x36 0x6 >,
			             < 0x37 0x6 >,
			             < 0x38 0x6 >,
			             < 0x39 0x6 >,
			             < 0x3a 0x6 >,
			             < 0x3b 0x6 >,
			             < 0x3c 0x6 >,
			             < 0x3d 0x6 >,
			             < 0x3e 0x6 >,
			             < 0x3f 0x6 >,
			             < 0x40 0x6 >,
			             < 0x41 0x6 >;        /* in zephyr/dts/arm/infineon/cat1a/psoc6_01/psoc6_01.dtsi:609 */
			status = "disabled";              /* in zephyr/dts/arm/infineon/cat1a/psoc6_01/psoc6_01.dtsi:625 */
		};
	};

	/* node '/cpus' defined in zephyr/dts/arm/infineon/cat1a/psoc6_01/psoc6_01.dtsi:11 */
	cpus {
		#address-cells = < 0x1 >; /* in zephyr/dts/arm/infineon/cat1a/psoc6_01/psoc6_01.dtsi:12 */
		#size-cells = < 0x0 >;    /* in zephyr/dts/arm/infineon/cat1a/psoc6_01/psoc6_01.dtsi:13 */

		/* node '/cpus/cpu@0' defined in zephyr/dts/arm/infineon/cat1a/psoc6_01/psoc6_01.dtsi:15 */
		cpu@0 {
			device_type = "cpu";           /* in zephyr/dts/arm/infineon/cat1a/psoc6_01/psoc6_01.dtsi:16 */
			compatible = "arm,cortex-m0+"; /* in zephyr/dts/arm/infineon/cat1a/psoc6_01/psoc6_01.dtsi:17 */
			reg = < 0x0 >;                 /* in zephyr/dts/arm/infineon/cat1a/psoc6_01/psoc6_01.dtsi:18 */
		};

		/* node '/cpus/cpu@1' defined in zephyr/dts/arm/infineon/cat1a/psoc6_01/psoc6_01.dtsi:21 */
		cpu@1 {
			device_type = "cpu";           /* in zephyr/dts/arm/infineon/cat1a/psoc6_01/psoc6_01.dtsi:22 */
			compatible = "arm,cortex-m4f"; /* in zephyr/dts/arm/infineon/cat1a/psoc6_01/psoc6_01.dtsi:23 */
			reg = < 0x1 >;                 /* in zephyr/dts/arm/infineon/cat1a/psoc6_01/psoc6_01.dtsi:24 */
		};
	};

	/* node '/flash-controller@40250000' defined in zephyr/dts/arm/infineon/cat1a/psoc6_01/psoc6_01.dtsi:28 */
	flash-controller@40250000 {
		compatible = "infineon,cat1-flash-controller"; /* in zephyr/dts/arm/infineon/cat1a/psoc6_01/psoc6_01.dtsi:29 */
		reg = < 0x40250000 0x10000 >;                  /* in zephyr/dts/arm/infineon/cat1a/psoc6_01/psoc6_01.dtsi:30 */
		#address-cells = < 0x1 >;                      /* in zephyr/dts/arm/infineon/cat1a/psoc6_01/psoc6_01.dtsi:31 */
		#size-cells = < 0x1 >;                         /* in zephyr/dts/arm/infineon/cat1a/psoc6_01/psoc6_01.dtsi:32 */

		/* node '/flash-controller@40250000/flash@10000000' defined in zephyr/dts/arm/infineon/cat1a/psoc6_01/psoc6_01.dtsi:34 */
		flash0: flash@10000000 {
			compatible = "soc-nv-flash";   /* in zephyr/dts/arm/infineon/cat1a/psoc6_01/psoc6_01.dtsi:35 */
			reg = < 0x10000000 0x100000 >; /* in zephyr/dts/arm/infineon/cat1a/psoc6_01/psoc6_01.dtsi:36 */
			write-block-size = < 0x200 >;  /* in zephyr/dts/arm/infineon/cat1a/psoc6_01/psoc6_01.dtsi:37 */
			erase-block-size = < 0x200 >;  /* in zephyr/dts/arm/infineon/cat1a/psoc6_01/psoc6_01.dtsi:38 */
		};

		/* node '/flash-controller@40250000/flash@14000000' defined in zephyr/dts/arm/infineon/cat1a/psoc6_01/psoc6_01.dtsi:41 */
		flash1: flash@14000000 {
			compatible = "soc-nv-flash";  /* in zephyr/dts/arm/infineon/cat1a/psoc6_01/psoc6_01.dtsi:42 */
			reg = < 0x14000000 0x8000 >;  /* in zephyr/dts/arm/infineon/cat1a/psoc6_01/psoc6_01.dtsi:43 */
			write-block-size = < 0x200 >; /* in zephyr/dts/arm/infineon/cat1a/psoc6_01/psoc6_01.dtsi:44 */
			erase-block-size = < 0x200 >; /* in zephyr/dts/arm/infineon/cat1a/psoc6_01/psoc6_01.dtsi:45 */
		};
	};

	/* node '/memory@8000000' defined in zephyr/dts/arm/infineon/cat1a/psoc6_01/psoc6_01.dtsi:49 */
	sram0: memory@8000000 {
		compatible = "mmio-sram";    /* in zephyr/dts/arm/infineon/cat1a/psoc6_01/psoc6_01.dtsi:50 */
		reg = < 0x8000000 0x48000 >; /* in zephyr/dts/arm/infineon/cat1a/psoc6_01/psoc6_01.dtsi:51 */
	};

	/* node '/clocks' defined in zephyr/dts/arm/infineon/cat1a/system_clocks.dtsi:9 */
	clocks {

		/* node '/clocks/clk_imo' defined in zephyr/dts/arm/infineon/cat1a/system_clocks.dtsi:11 */
		clk_imo: clk_imo {
			#clock-cells = < 0x0 >;         /* in zephyr/dts/arm/infineon/cat1a/system_clocks.dtsi:12 */
			compatible = "fixed-clock";     /* in zephyr/dts/arm/infineon/cat1a/system_clocks.dtsi:13 */
			clock-frequency = < 0x7a1200 >; /* in zephyr/dts/arm/infineon/cat1a/system_clocks.dtsi:14 */
			status = "okay";                /* in zephyr/dts/arm/infineon/cat1a/system_clocks.dtsi:15 */
			phandle = < 0x4 >;              /* in zephyr/dts/arm/infineon/cat1a/system_clocks.dtsi:22 */
		};

		/* node '/clocks/path_mux0' defined in zephyr/dts/arm/infineon/cat1a/system_clocks.dtsi:19 */
		path_mux0: path_mux0 {
			#clock-cells = < 0x0 >;            /* in zephyr/dts/arm/infineon/cat1a/system_clocks.dtsi:20 */
			compatible = "fixed-factor-clock"; /* in zephyr/dts/arm/infineon/cat1a/system_clocks.dtsi:21 */
			clocks = < &clk_imo >;             /* in zephyr/dts/arm/infineon/cat1a/system_clocks.dtsi:22 */
			status = "okay";                   /* in zephyr/dts/arm/infineon/cat1a/system_clocks.dtsi:23 */
		};

		/* node '/clocks/path_mux1' defined in zephyr/dts/arm/infineon/cat1a/system_clocks.dtsi:27 */
		path_mux1: path_mux1 {
			#clock-cells = < 0x0 >;            /* in zephyr/dts/arm/infineon/cat1a/system_clocks.dtsi:28 */
			compatible = "fixed-factor-clock"; /* in zephyr/dts/arm/infineon/cat1a/system_clocks.dtsi:29 */
			clocks = < &clk_imo >;             /* in zephyr/dts/arm/infineon/cat1a/system_clocks.dtsi:30 */
			status = "okay";                   /* in zephyr/dts/arm/infineon/cat1a/system_clocks.dtsi:31 */
			phandle = < 0x6 >;                 /* in zephyr/dts/arm/infineon/cat1a/system_clocks.dtsi:88 */
		};

		/* node '/clocks/path_mux2' defined in zephyr/dts/arm/infineon/cat1a/system_clocks.dtsi:35 */
		path_mux2: path_mux2 {
			#clock-cells = < 0x0 >;            /* in zephyr/dts/arm/infineon/cat1a/system_clocks.dtsi:36 */
			compatible = "fixed-factor-clock"; /* in zephyr/dts/arm/infineon/cat1a/system_clocks.dtsi:37 */
			clocks = < &clk_imo >;             /* in zephyr/dts/arm/infineon/cat1a/system_clocks.dtsi:38 */
			status = "disabled";               /* in zephyr/dts/arm/infineon/cat1a/system_clocks.dtsi:39 */
			phandle = < 0x7 >;                 /* in zephyr/dts/arm/infineon/cat1a/system_clocks.dtsi:97 */
		};

		/* node '/clocks/path_mux3' defined in zephyr/dts/arm/infineon/cat1a/system_clocks.dtsi:43 */
		path_mux3: path_mux3 {
			#clock-cells = < 0x0 >;            /* in zephyr/dts/arm/infineon/cat1a/system_clocks.dtsi:44 */
			compatible = "fixed-factor-clock"; /* in zephyr/dts/arm/infineon/cat1a/system_clocks.dtsi:45 */
			clocks = < &clk_imo >;             /* in zephyr/dts/arm/infineon/cat1a/system_clocks.dtsi:46 */
			status = "disabled";               /* in zephyr/dts/arm/infineon/cat1a/system_clocks.dtsi:47 */
			phandle = < 0x8 >;                 /* in zephyr/dts/arm/infineon/cat1a/system_clocks.dtsi:106 */
		};

		/* node '/clocks/path_mux4' defined in zephyr/dts/arm/infineon/cat1a/system_clocks.dtsi:51 */
		path_mux4: path_mux4 {
			#clock-cells = < 0x0 >;            /* in zephyr/dts/arm/infineon/cat1a/system_clocks.dtsi:52 */
			compatible = "fixed-factor-clock"; /* in zephyr/dts/arm/infineon/cat1a/system_clocks.dtsi:53 */
			clocks = < &clk_imo >;             /* in zephyr/dts/arm/infineon/cat1a/system_clocks.dtsi:54 */
			status = "disabled";               /* in zephyr/dts/arm/infineon/cat1a/system_clocks.dtsi:55 */
			phandle = < 0x9 >;                 /* in zephyr/dts/arm/infineon/cat1a/system_clocks.dtsi:115 */
		};

		/* node '/clocks/fll0' defined in zephyr/dts/arm/infineon/cat1a/system_clocks.dtsi:59 */
		fll0: fll0 {
			#clock-cells = < 0x0 >;          /* in zephyr/dts/arm/infineon/cat1a/system_clocks.dtsi:60 */
			compatible = "fixed-clock";      /* in zephyr/dts/arm/infineon/cat1a/system_clocks.dtsi:61 */
			status = "okay";                 /* in zephyr/boards/infineon/cy8cproto_063_ble/cy8cproto_063_ble.dts:95 */
			clock-frequency = < 0x5f5e100 >; /* in zephyr/boards/infineon/cy8cproto_063_ble/cy8cproto_063_ble.dts:96 */
			phandle = < 0x5 >;               /* in zephyr/boards/infineon/cy8cproto_063_ble/cy8cproto_063_ble.dts:101 */
		};

		/* node '/clocks/pll0' defined in zephyr/dts/arm/infineon/cat1a/system_clocks.dtsi:67 */
		pll0: pll0 {
			#clock-cells = < 0x0 >;     /* in zephyr/dts/arm/infineon/cat1a/system_clocks.dtsi:68 */
			compatible = "fixed-clock"; /* in zephyr/dts/arm/infineon/cat1a/system_clocks.dtsi:69 */
			status = "disabled";        /* in zephyr/dts/arm/infineon/cat1a/system_clocks.dtsi:71 */
		};

		/* node '/clocks/clk_hf0' defined in zephyr/dts/arm/infineon/cat1a/system_clocks.dtsi:75 */
		clk_hf0: clk_hf0 {
			#clock-cells = < 0x0 >;            /* in zephyr/dts/arm/infineon/cat1a/system_clocks.dtsi:76 */
			compatible = "fixed-factor-clock"; /* in zephyr/dts/arm/infineon/cat1a/system_clocks.dtsi:77 */
			status = "okay";                   /* in zephyr/dts/arm/infineon/cat1a/system_clocks.dtsi:80 */
			clock-div = < 0x1 >;               /* in zephyr/boards/infineon/cy8cproto_063_ble/cy8cproto_063_ble.dts:100 */
			clocks = < &fll0 >;                /* in zephyr/boards/infineon/cy8cproto_063_ble/cy8cproto_063_ble.dts:101 */
		};

		/* node '/clocks/clk_hf1' defined in zephyr/dts/arm/infineon/cat1a/system_clocks.dtsi:84 */
		clk_hf1: clk_hf1 {
			#clock-cells = < 0x0 >;            /* in zephyr/dts/arm/infineon/cat1a/system_clocks.dtsi:85 */
			compatible = "fixed-factor-clock"; /* in zephyr/dts/arm/infineon/cat1a/system_clocks.dtsi:86 */
			clock-div = < 0x1 >;               /* in zephyr/dts/arm/infineon/cat1a/system_clocks.dtsi:87 */
			clocks = < &path_mux1 >;           /* in zephyr/dts/arm/infineon/cat1a/system_clocks.dtsi:88 */
			status = "disabled";               /* in zephyr/dts/arm/infineon/cat1a/system_clocks.dtsi:89 */
		};

		/* node '/clocks/clk_hf2' defined in zephyr/dts/arm/infineon/cat1a/system_clocks.dtsi:93 */
		clk_hf2: clk_hf2 {
			#clock-cells = < 0x0 >;            /* in zephyr/dts/arm/infineon/cat1a/system_clocks.dtsi:94 */
			compatible = "fixed-factor-clock"; /* in zephyr/dts/arm/infineon/cat1a/system_clocks.dtsi:95 */
			clock-div = < 0x1 >;               /* in zephyr/dts/arm/infineon/cat1a/system_clocks.dtsi:96 */
			clocks = < &path_mux2 >;           /* in zephyr/dts/arm/infineon/cat1a/system_clocks.dtsi:97 */
			status = "disabled";               /* in zephyr/dts/arm/infineon/cat1a/system_clocks.dtsi:98 */
		};

		/* node '/clocks/clk_hf3' defined in zephyr/dts/arm/infineon/cat1a/system_clocks.dtsi:102 */
		clk_hf3: clk_hf3 {
			#clock-cells = < 0x0 >;            /* in zephyr/dts/arm/infineon/cat1a/system_clocks.dtsi:103 */
			compatible = "fixed-factor-clock"; /* in zephyr/dts/arm/infineon/cat1a/system_clocks.dtsi:104 */
			clock-div = < 0x1 >;               /* in zephyr/dts/arm/infineon/cat1a/system_clocks.dtsi:105 */
			clocks = < &path_mux3 >;           /* in zephyr/dts/arm/infineon/cat1a/system_clocks.dtsi:106 */
			status = "disabled";               /* in zephyr/dts/arm/infineon/cat1a/system_clocks.dtsi:107 */
		};

		/* node '/clocks/clk_hf4' defined in zephyr/dts/arm/infineon/cat1a/system_clocks.dtsi:111 */
		clk_hf4: clk_hf4 {
			#clock-cells = < 0x0 >;            /* in zephyr/dts/arm/infineon/cat1a/system_clocks.dtsi:112 */
			compatible = "fixed-factor-clock"; /* in zephyr/dts/arm/infineon/cat1a/system_clocks.dtsi:113 */
			clock-div = < 0x1 >;               /* in zephyr/dts/arm/infineon/cat1a/system_clocks.dtsi:114 */
			clocks = < &path_mux4 >;           /* in zephyr/dts/arm/infineon/cat1a/system_clocks.dtsi:115 */
			status = "disabled";               /* in zephyr/dts/arm/infineon/cat1a/system_clocks.dtsi:116 */
		};

		/* node '/clocks/clk_fast' defined in zephyr/dts/arm/infineon/cat1a/system_clocks.dtsi:120 */
		clk_fast: clk_fast {
			#clock-cells = < 0x0 >;            /* in zephyr/dts/arm/infineon/cat1a/system_clocks.dtsi:121 */
			compatible = "fixed-factor-clock"; /* in zephyr/dts/arm/infineon/cat1a/system_clocks.dtsi:122 */
			status = "okay";                   /* in zephyr/dts/arm/infineon/cat1a/system_clocks.dtsi:124 */
			clock-div = < 0x1 >;               /* in zephyr/boards/infineon/cy8cproto_063_ble/cy8cproto_063_ble.dts:108 */
		};

		/* node '/clocks/clk_slow' defined in zephyr/dts/arm/infineon/cat1a/system_clocks.dtsi:128 */
		clk_slow: clk_slow {
			#clock-cells = < 0x0 >;            /* in zephyr/dts/arm/infineon/cat1a/system_clocks.dtsi:129 */
			compatible = "fixed-factor-clock"; /* in zephyr/dts/arm/infineon/cat1a/system_clocks.dtsi:130 */
			status = "okay";                   /* in zephyr/dts/arm/infineon/cat1a/system_clocks.dtsi:132 */
			clock-div = < 0x2 >;               /* in zephyr/boards/infineon/cy8cproto_063_ble/cy8cproto_063_ble.dts:115 */
		};

		/* node '/clocks/clk_peri' defined in zephyr/dts/arm/infineon/cat1a/system_clocks.dtsi:136 */
		clk_peri: clk_peri {
			#clock-cells = < 0x0 >;            /* in zephyr/dts/arm/infineon/cat1a/system_clocks.dtsi:137 */
			compatible = "fixed-factor-clock"; /* in zephyr/dts/arm/infineon/cat1a/system_clocks.dtsi:138 */
			status = "okay";                   /* in zephyr/dts/arm/infineon/cat1a/system_clocks.dtsi:140 */
			clock-div = < 0x1 >;               /* in zephyr/boards/infineon/cy8cproto_063_ble/cy8cproto_063_ble.dts:122 */
		};
	};

	/* node '/leds' defined in zephyr/boards/infineon/cy8cproto_063_ble/cy8cproto_063_ble.dts:35 */
	leds {
		compatible = "gpio-leds"; /* in zephyr/boards/infineon/cy8cproto_063_ble/cy8cproto_063_ble.dts:36 */

		/* node '/leds/led_0' defined in zephyr/boards/infineon/cy8cproto_063_ble/cy8cproto_063_ble.dts:38 */
		user_led: led_0 {
			label = "LED_0";                /* in zephyr/boards/infineon/cy8cproto_063_ble/cy8cproto_063_ble.dts:39 */
			gpios = < &gpio_prt6 0x3 0x1 >; /* in zephyr/boards/infineon/cy8cproto_063_ble/cy8cproto_063_ble.dts:40 */
		};
	};

	/* node '/gpio_keys' defined in zephyr/boards/infineon/cy8cproto_063_ble/cy8cproto_063_ble.dts:44 */
	gpio_keys {
		compatible = "gpio-keys"; /* in zephyr/boards/infineon/cy8cproto_063_ble/cy8cproto_063_ble.dts:45 */

		/* node '/gpio_keys/button_0' defined in zephyr/boards/infineon/cy8cproto_063_ble/cy8cproto_063_ble.dts:47 */
		user_bt: button_0 {
			label = "SW_0";                  /* in zephyr/boards/infineon/cy8cproto_063_ble/cy8cproto_063_ble.dts:48 */
			gpios = < &gpio_prt0 0x4 0x11 >; /* in zephyr/boards/infineon/cy8cproto_063_ble/cy8cproto_063_ble.dts:49 */
			zephyr,code = < 0xb >;           /* in zephyr/boards/infineon/cy8cproto_063_ble/cy8cproto_063_ble.dts:50 */
		};
	};
};
